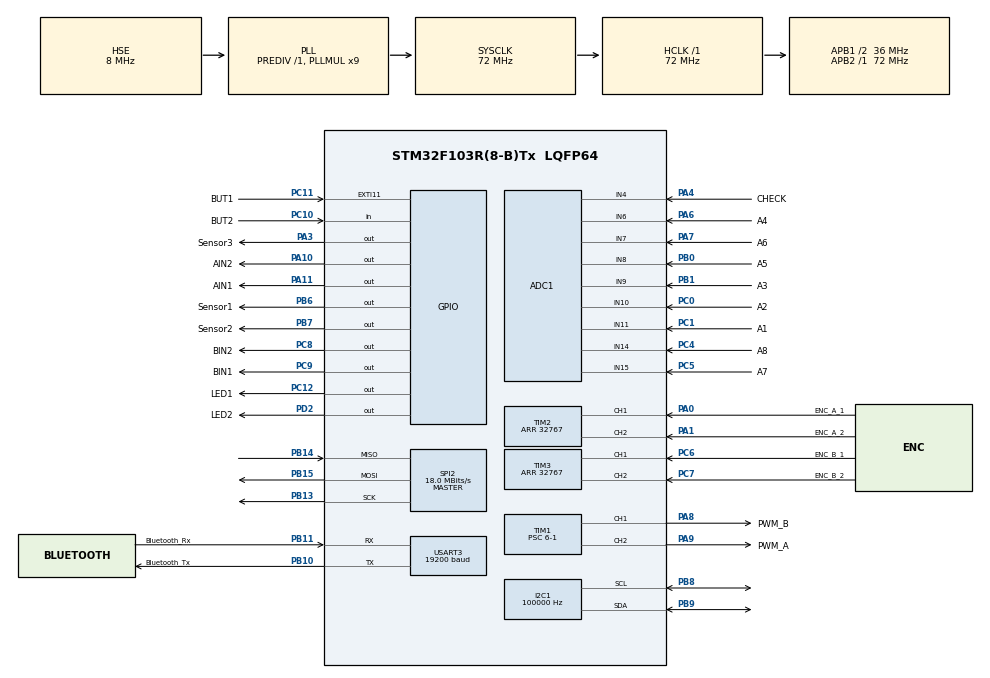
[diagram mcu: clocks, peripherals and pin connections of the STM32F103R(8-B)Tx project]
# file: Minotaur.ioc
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ADC1.Channel-361\#ChannelRegularConversion=ADC_CHANNEL_11
ADC1.Channel-367\#ChannelRegularConversion=ADC_CHANNEL_10
ADC1.Channel-368\#ChannelRegularConversion=ADC_CHANNEL_9
ADC1.Channel-369\#ChannelRegularConversion=ADC_CHANNEL_6
ADC1.Channel-370\#ChannelRegularConversion=ADC_CHANNEL_8
ADC1.Channel-371\#ChannelRegularConversion=ADC_CHANNEL_7
ADC1.ContinuousConvMode=ENABLE
ADC1.DataAlign=ADC_DATAALIGN_RIGHT
ADC1.DiscontinuousConvMode=DISABLE
ADC1.EnableAnalogWatchDog=false
ADC1.EnableRegularConversion=ENABLE
ADC1.ExternalTrigConvEdgeChoice=NONE
ADC1.InjNumberOfConversion=0
ADC1.NbrOfConversion=6
ADC1.NbrOfConversionFlag=1
ADC1.Rank-361\#ChannelRegularConversion=1
ADC1.Rank-367\#ChannelRegularConversion=2
ADC1.Rank-368\#ChannelRegularConversion=3
ADC1.Rank-369\#ChannelRegularConversion=4
ADC1.Rank-370\#ChannelRegularConversion=5
ADC1.Rank-371\#ChannelRegularConversion=6
ADC1.SamplingTime-361\#ChannelRegularConversion=ADC_SAMPLETIME_41CYCLES_5
ADC1.SamplingTime-367\#ChannelRegularConversion=ADC_SAMPLETIME_41CYCLES_5
ADC1.SamplingTime-368\#ChannelRegularConversion=ADC_SAMPLETIME_41CYCLES_5
ADC1.SamplingTime-369\#ChannelRegularConversion=ADC_SAMPLETIME_41CYCLES_5
ADC1.SamplingTime-370\#ChannelRegularConversion=ADC_SAMPLETIME_41CYCLES_5
ADC1.SamplingTime-371\#ChannelRegularConversion=ADC_SAMPLETIME_41CYCLES_5
ADC1.ScanConvMode=ADC_SCAN_ENABLE
ADC1.master=1
Dma.ADC1.0.Direction=DMA_PERIPH_TO_MEMORY
Dma.ADC1.0.Instance=DMA1_Channel1
Dma.ADC1.0.MemDataAlignment=DMA_MDATAALIGN_HALFWORD
Dma.ADC1.0.MemInc=DMA_MINC_ENABLE
Dma.ADC1.0.Mode=DMA_CIRCULAR
Dma.ADC1.0.PeriphDataAlignment=DMA_PDATAALIGN_HALFWORD
Dma.ADC1.0.PeriphInc=DMA_PINC_DISABLE
Dma.ADC1.0.Priority=DMA_PRIORITY_LOW
Dma.Request0=ADC1
Dma.Request1=USART3_TX
Dma.Request2=USART3_RX
Dma.USART3_RX.2.Direction=DMA_PERIPH_TO_MEMORY
Dma.USART3_RX.2.Instance=DMA1_Channel3
Dma.USART3_RX.2.MemDataAlignment=DMA_MDATAALIGN_BYTE
Dma.USART3_RX.2.MemInc=DMA_MINC_ENABLE
Dma.USART3_RX.2.Mode=DMA_CIRCULAR
Dma.USART3_RX.2.PeriphDataAlignment=DMA_PDATAALIGN_BYTE
Dma.USART3_RX.2.PeriphInc=DMA_PINC_DISABLE
Dma.USART3_RX.2.Priority=DMA_PRIORITY_LOW
Dma.USART3_TX.1.Direction=DMA_MEMORY_TO_PERIPH
Dma.USART3_TX.1.Instance=DMA1_Channel2
Dma.USART3_TX.1.MemDataAlignment=DMA_MDATAALIGN_BYTE
Dma.USART3_TX.1.MemInc=DMA_MINC_ENABLE
Dma.USART3_TX.1.Mode=DMA_NORMAL
Dma.USART3_TX.1.PeriphDataAlignment=DMA_PDATAALIGN_BYTE
Dma.USART3_TX.1.PeriphInc=DMA_PINC_DISABLE
Dma.USART3_TX.1.Priority=DMA_PRIORITY_LOW
I2C1.ClockSpeed=100000
I2C1.OwnAddress=0
Mcu.Family=STM32F1
Mcu.Name=STM32F103R(8-B)Tx
Mcu.Package=LQFP64
NVIC.DMA1_Channel1_IRQn=true\:1\:0\:true
NVIC.DMA1_Channel2_IRQn=true\:2\:0\:true
NVIC.DMA1_Channel3_IRQn=true\:2\:0\:true
NVIC.EXTI15_10_IRQn=true\:0\:0\:false
NVIC.PriorityGroup=NVIC_PRIORITYGROUP_4
NVIC.TIM4_IRQn=true\:0\:0\:false
NVIC.USART3_IRQn=true\:2\:0\:true
PA0-WKUP.GPIO_Label=ENC_A_1
PA0-WKUP.GPIO_PuPd=GPIO_NOPULL
PA0-WKUP.Signal=S_TIM2_CH1_ETR
PA1.GPIO_Label=ENC_A_2
PA1.GPIO_PuPd=GPIO_NOPULL
PA1.Signal=S_TIM2_CH2
PA10.GPIO_Label=AIN2
PA10.Signal=GPIO_Output
PA11.GPIO_Label=AIN1
PA11.Signal=GPIO_Output
PA13.Mode=Trace_Asynchronous_SW
PA13.Signal=SYS_JTMS-SWDIO
PA14.Mode=Trace_Asynchronous_SW
PA14.Signal=SYS_JTCK-SWCLK
PA3.GPIO_Label=Sensor3
PA3.Signal=GPIO_Output
PA4.GPIO_Label=CHECK
PA4.Signal=ADCx_IN4
PA6.GPIO_Label=A4
PA6.Signal=ADCx_IN6
PA7.GPIO_Label=A6
PA7.Signal=ADCx_IN7
PA8.GPIO_Label=PWM_B
PA8.Signal=S_TIM1_CH1
PA9.GPIO_Label=PWM_A
PA9.Signal=S_TIM1_CH2
PB0.GPIO_Label=A5
PB0.Signal=ADCx_IN8
PB1.GPIO_Label=A3
PB1.Signal=ADCx_IN9
PB10.GPIO_Label=Bluetooth_Tx
PB10.Mode=Asynchronous
PB10.Signal=USART3_TX
PB11.GPIO_Label=Bluetooth_Rx
PB11.Mode=Asynchronous
PB11.Signal=USART3_RX
PB13.Mode=Full_Duplex_Master
PB13.Signal=SPI2_SCK
PB14.Mode=Full_Duplex_Master
PB14.Signal=SPI2_MISO
PB15.Mode=Full_Duplex_Master
PB15.Signal=SPI2_MOSI
PB3.Mode=Trace_Asynchronous_SW
PB3.Signal=SYS_JTDO-TRACESWO
PB6.GPIO_Label=Sensor1
PB6.Signal=GPIO_Output
PB7.GPIO_Label=Sensor2
PB7.Signal=GPIO_Output
PB8.Mode=I2C
PB8.Signal=I2C1_SCL
PB9.Mode=I2C
PB9.Signal=I2C1_SDA
PC0.GPIO_Label=A2
PC0.Signal=ADCx_IN10
PC1.GPIO_Label=A1
PC1.Signal=ADCx_IN11
PC10.GPIO_Label=BUT2
PC10.Signal=GPIO_Input
PC11.GPIO_Label=BUT1
PC11.Signal=GPXTI11
PC12.GPIO_Label=LED1
PC12.Signal=GPIO_Output
PC14-OSC32_IN.Mode=LSE-External-Oscillator
PC14-OSC32_IN.Signal=RCC_OSC32_IN
PC15-OSC32_OUT.Mode=LSE-External-Oscillator
PC15-OSC32_OUT.Signal=RCC_OSC32_OUT
PC4.GPIO_Label=A8
PC4.Signal=ADCx_IN14
PC5.GPIO_Label=A7
PC5.Signal=ADCx_IN15
PC6.GPIO_Label=ENC_B_1
PC6.Signal=S_TIM3_CH1
PC7.GPIO_Label=ENC_B_2
PC7.Signal=S_TIM3_CH2
PC8.GPIO_Label=BIN2
PC8.Signal=GPIO_Output
PC9.GPIO_Label=BIN1
PC9.Signal=GPIO_Output
PD0-OSC_IN.Mode=HSE-External-Oscillator
PD0-OSC_IN.Signal=RCC_OSC_IN
PD1-OSC_OUT.Mode=HSE-External-Oscillator
PD1-OSC_OUT.Signal=RCC_OSC_OUT
PD2.GPIO_Label=LED2
PD2.Signal=GPIO_Output
ProjectManager.TargetToolchain=TrueSTUDIO
RCC.ADCPresc=RCC_ADCPCLK2_DIV6
RCC.AHBFreq_Value=72000000
RCC.APB1CLKDivider=RCC_HCLK_DIV2
RCC.APB1Freq_Value=36000000
RCC.APB1TimFreq_Value=72000000
RCC.APB2Freq_Value=72000000
RCC.APB2TimFreq_Value=72000000
RCC.HCLKFreq_Value=72000000
RCC.HSIState=RCC_HSI_ON
RCC.PLLMUL=RCC_PLL_MUL9
RCC.PLLSourceVirtual=RCC_PLLSOURCE_HSE
RCC.SYSCLKFreq_VALUE=72000000
RCC.SYSCLKSource=RCC_SYSCLKSOURCE_PLLCLK
RCC.USBFreq_Value=72000000
SH.ADCx_IN10.0=ADC1_IN10,IN10
SH.ADCx_IN11.0=ADC1_IN11,IN11
SH.ADCx_IN14.0=ADC1_IN14,IN14
SH.ADCx_IN15.0=ADC1_IN15,IN15
SH.ADCx_IN4.0=ADC1_IN4,IN4
SH.ADCx_IN6.0=ADC1_IN6,IN6
SH.ADCx_IN7.0=ADC1_IN7,IN7
SH.ADCx_IN8.0=ADC1_IN8,IN8
SH.ADCx_IN9.0=ADC1_IN9,IN9
SH.S_TIM1_CH1.0=TIM1_CH1,PWM Generation1 CH1
SH.S_TIM1_CH2.0=TIM1_CH2,PWM Generation2 CH2
SH.S_TIM2_CH1_ETR.0=TIM2_CH1,Encoder_Interface
SH.S_TIM2_CH2.0=TIM2_CH2,Encoder_Interface
SH.S_TIM3_CH1.0=TIM3_CH1,Encoder_Interface
SH.S_TIM3_CH2.0=TIM3_CH2,Encoder_Interface
SPI2.CalculateBaudRate=18.0 MBits/s
SPI2.Mode=SPI_MODE_MASTER
TIM1.Channel-PWM\ Generation2\ CH2=TIM_CHANNEL_2
TIM1.OCMode_PWM-PWM\ Generation2\ CH2=TIM_OCMODE_PWM1
TIM1.Period=999
TIM1.Prescaler=6-1
TIM2.CounterMode=TIM_COUNTERMODE_UP
TIM2.EncoderMode=TIM_ENCODERMODE_TI12
TIM2.IC1Polarity=TIM_ICPOLARITY_RISING
TIM2.IC2Polarity=TIM_ICPOLARITY_FALLING
TIM2.Period=32767
TIM3.CounterMode=TIM_COUNTERMODE_UP
TIM3.EncoderMode=TIM_ENCODERMODE_TI12
TIM3.IC2Polarity=TIM_ICPOLARITY_FALLING
TIM3.Period=32767
TIM4.Period=1000-1
TIM4.Prescaler=72-1
TIM4.TIM_MasterOutputTrigger=TIM_TRGO_ENABLE
USART3.BaudRate=19200
VP_RTC_No_RTC_Output.Mode=RTC OUT
VP_TIM1_VS_ClockSourceINT.Mode=Internal
VP_TIM4_VS_ClockSourceINT.Mode=Internal
board=Minotaur

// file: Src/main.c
/**
  ******************************************************************************
  * File Name          : main.c
  * Description        : Main program body
  ******************************************************************************
  *
  * COPYRIGHT(c) 2016 STMicroelectronics
  *
  * Redistribution and use in source and binary forms, with or without modification,
  * are permitted provided that the following conditions are met:
  *   1. Redistributions of source code must retain the above copyright notice,
  *      this list of conditions and the following disclaimer.
  *   2. Redistributions in binary form must reproduce the above copyright notice,
  *      this list of conditions and the following disclaimer in the documentation
  *      and/or other materials provided with the distribution.
  *   3. Neither the name of STMicroelectronics nor the names of its contributors
  *      may be used to endorse or promote products derived from this software
  *      without specific prior written permission.
  *
  * THIS SOFTWARE IS PROVIDED BY THE COPYRIGHT HOLDERS AND CONTRIBUTORS "AS IS"
  * AND ANY EXPRESS OR IMPLIED WARRANTIES, INCLUDING, BUT NOT LIMITED TO, THE
  * IMPLIED WARRANTIES OF MERCHANTABILITY AND FITNESS FOR A PARTICULAR PURPOSE ARE
  * DISCLAIMED. IN NO EVENT SHALL THE COPYRIGHT HOLDER OR CONTRIBUTORS BE LIABLE
  * FOR ANY DIRECT, INDIRECT, INCIDENTAL, SPECIAL, EXEMPLARY, OR CONSEQUENTIAL
  * DAMAGES (INCLUDING, BUT NOT LIMITED TO, PROCUREMENT OF SUBSTITUTE GOODS OR
  * SERVICES; LOSS OF USE, DATA, OR PROFITS; OR BUSINESS INTERRUPTION) HOWEVER
  * CAUSED AND ON ANY THEORY OF LIABILITY, WHETHER IN CONTRACT, STRICT LIABILITY,
  * OR TORT (INCLUDING NEGLIGENCE OR OTHERWISE) ARISING IN ANY WAY OUT OF THE USE
  * OF THIS SOFTWARE, EVEN IF ADVISED OF THE POSSIBILITY OF SUCH DAMAGE.
  *
  ******************************************************************************
  */
#include "stm32f1xx_hal.h"

/* USER CODE BEGIN Includes */
#include "main.h"
/* USER CODE END Includes */

ADC_HandleTypeDef hadc1;
DMA_HandleTypeDef hdma_adc1;

I2C_HandleTypeDef hi2c1;

RTC_HandleTypeDef hrtc;

SPI_HandleTypeDef hspi2;

TIM_HandleTypeDef htim1;
TIM_HandleTypeDef htim2;
TIM_HandleTypeDef htim3;
TIM_HandleTypeDef htim4;

UART_HandleTypeDef huart3;
DMA_HandleTypeDef hdma_usart3_tx;
DMA_HandleTypeDef hdma_usart3_rx;

/* USER CODE BEGIN PV */
/* Private variables ---------------------------------------------------------*/

/* USER CODE END PV */

void SystemClock_Config(void);
static void MX_GPIO_Init(void);
static void MX_DMA_Init(void);
static void MX_ADC1_Init(void);
static void MX_I2C1_Init(void);
static void MX_RTC_Init(void);
static void MX_SPI2_Init(void);
static void MX_TIM1_Init(void);
static void MX_TIM2_Init(void);
static void MX_TIM3_Init(void);
static void MX_TIM4_Init(void);
static void MX_USART3_UART_Init(void);

/* USER CODE BEGIN PFP */
/* Private function prototypes -----------------------------------------------*/

/* USER CODE END PFP */

int main(void)
{

  /* MCU Configuration----------------------------------------------------------*/

  /* Reset of all peripherals, Initializes the Flash interface and the Systick. */
  HAL_Init();

  /* Configure the system clock */
  SystemClock_Config();

  /* Initialize all configured peripherals */
  MX_GPIO_Init();
  MX_DMA_Init();
  MX_ADC1_Init();
  MX_I2C1_Init();
  MX_RTC_Init();
  MX_SPI2_Init();
  MX_TIM1_Init();
  MX_TIM2_Init();
  MX_TIM3_Init();
  MX_TIM4_Init();
  MX_USART3_UART_Init();

  /* USER CODE BEGIN 2 */
	encoderInit();
	pwmInit();
//	adcInit();
	uartInit();
	timInterruptInit();
	gyroInit(GYROHIGH);
	calibrateGyro();

//	rotaryRight(800);
//	HAL_Delay(500);
//	rotaryLeft(800);
	drive(VEL);

  /* USER CODE END 2 */

  /* Infinite loop */
  while (1)
  {

  }

}

/** System Clock Configuration
*/
void SystemClock_Config(void)
{

  RCC_OscInitTypeDef RCC_OscInitStruct;
  RCC_ClkInitTypeDef RCC_ClkInitStruct;
  RCC_PeriphCLKInitTypeDef PeriphClkInit;

  RCC_OscInitStruct.OscillatorType = RCC_OSCILLATORTYPE_LSI|RCC_OSCILLATORTYPE_HSE;
  RCC_OscInitStruct.HSEState = RCC_HSE_ON;
  RCC_OscInitStruct.HSEPredivValue = RCC_HSE_PREDIV_DIV1;
  RCC_OscInitStruct.LSIState = RCC_LSI_ON;
  RCC_OscInitStruct.PLL.PLLState = RCC_PLL_ON;
  RCC_OscInitStruct.PLL.PLLSource = RCC_PLLSOURCE_HSE;
  RCC_OscInitStruct.PLL.PLLMUL = RCC_PLL_MUL9;
  HAL_RCC_OscConfig(&RCC_OscInitStruct);

  RCC_ClkInitStruct.ClockType = RCC_CLOCKTYPE_SYSCLK|RCC_CLOCKTYPE_PCLK1;
  RCC_ClkInitStruct.SYSCLKSource = RCC_SYSCLKSOURCE_PLLCLK;
  RCC_ClkInitStruct.AHBCLKDivider = RCC_SYSCLK_DIV1;
  RCC_ClkInitStruct.APB1CLKDivider = RCC_HCLK_DIV2;
  RCC_ClkInitStruct.APB2CLKDivider = RCC_HCLK_DIV1;
  HAL_RCC_ClockConfig(&RCC_ClkInitStruct, FLASH_LATENCY_2);

  PeriphClkInit.PeriphClockSelection = RCC_PERIPHCLK_RTC|RCC_PERIPHCLK_ADC;
  PeriphClkInit.RTCClockSelection = RCC_RTCCLKSOURCE_LSI;
  PeriphClkInit.AdcClockSelection = RCC_ADCPCLK2_DIV6;
  HAL_RCCEx_PeriphCLKConfig(&PeriphClkInit);

  HAL_SYSTICK_Config(HAL_RCC_GetHCLKFreq()/1000);

  HAL_SYSTICK_CLKSourceConfig(SYSTICK_CLKSOURCE_HCLK);

  /* SysTick_IRQn interrupt configuration */
  HAL_NVIC_SetPriority(SysTick_IRQn, 0, 0);
}

/* ADC1 init function */
void MX_ADC1_Init(void)
{

  ADC_ChannelConfTypeDef sConfig;

    /**Common config
    */
  hadc1.Instance = ADC1;
  hadc1.Init.ScanConvMode = ADC_SCAN_ENABLE;
  hadc1.Init.ContinuousConvMode = ENABLE;
  hadc1.Init.DiscontinuousConvMode = DISABLE;
  hadc1.Init.ExternalTrigConv = ADC_SOFTWARE_START;
  hadc1.Init.DataAlign = ADC_DATAALIGN_RIGHT;
  hadc1.Init.NbrOfConversion = 6;
  HAL_ADC_Init(&hadc1);

    /**Configure Regular Channel
    */
  sConfig.Channel = ADC_CHANNEL_11;
  sConfig.Rank = 1;
  sConfig.SamplingTime = ADC_SAMPLETIME_7CYCLES_5;
  HAL_ADC_ConfigChannel(&hadc1, &sConfig);

    /**Configure Regular Channel
    */
  sConfig.Channel = ADC_CHANNEL_10;
  sConfig.Rank = 2;
  HAL_ADC_ConfigChannel(&hadc1, &sConfig);

    /**Configure Regular Channel
    */
  sConfig.Channel = ADC_CHANNEL_9;
  sConfig.Rank = 3;
  HAL_ADC_ConfigChannel(&hadc1, &sConfig);

    /**Configure Regular Channel
    */
  sConfig.Channel = ADC_CHANNEL_6;
  sConfig.Rank = 4;
  HAL_ADC_ConfigChannel(&hadc1, &sConfig);

    /**Configure Regular Channel
    */
  sConfig.Channel = ADC_CHANNEL_8;
  sConfig.Rank = 5;
  HAL_ADC_ConfigChannel(&hadc1, &sConfig);

    /**Configure Regular Channel
    */
  sConfig.Channel = ADC_CHANNEL_7;
  sConfig.Rank = 6;
  HAL_ADC_ConfigChannel(&hadc1, &sConfig);

}

/* I2C1 init function */
void MX_I2C1_Init(void)
{

  hi2c1.Instance = I2C1;
  hi2c1.Init.ClockSpeed = 100000;
  hi2c1.Init.DutyCycle = I2C_DUTYCYCLE_2;
  hi2c1.Init.OwnAddress1 = 0;
  hi2c1.Init.AddressingMode = I2C_ADDRESSINGMODE_7BIT;
  hi2c1.Init.DualAddressMode = I2C_DUALADDRESS_DISABLED;
  hi2c1.Init.OwnAddress2 = 0;
  hi2c1.Init.GeneralCallMode = I2C_GENERALCALL_DISABLED;
  hi2c1.Init.NoStretchMode = I2C_NOSTRETCH_DISABLED;
  HAL_I2C_Init(&hi2c1);

}

/* RTC init function */
void MX_RTC_Init(void)
{

  RTC_TimeTypeDef sTime;
  RTC_DateTypeDef DateToUpdate;

    /**Initialize RTC and set the Time and Date
    */
  hrtc.Instance = RTC;
  hrtc.Init.AsynchPrediv = RTC_AUTO_1_SECOND;
  hrtc.Init.OutPut = RTC_OUTPUTSOURCE_NONE;
  HAL_RTC_Init(&hrtc);

  sTime.Hours = 0x0;
  sTime.Minutes = 0x0;
  sTime.Seconds = 0x0;

  HAL_RTC_SetTime(&hrtc, &sTime, FORMAT_BCD);

  DateToUpdate.WeekDay = RTC_WEEKDAY_MONDAY;
  DateToUpdate.Month = RTC_MONTH_JANUARY;
  DateToUpdate.Date = 0x1;
  DateToUpdate.Year = 0x0;

  HAL_RTC_SetDate(&hrtc, &DateToUpdate, FORMAT_BCD);

}

/* SPI2 init function */
void MX_SPI2_Init(void)
{

  hspi2.Instance = SPI2;
  hspi2.Init.Mode = SPI_MODE_MASTER;
  hspi2.Init.Direction = SPI_DIRECTION_2LINES;
  hspi2.Init.DataSize = SPI_DATASIZE_8BIT;
  hspi2.Init.CLKPolarity = SPI_POLARITY_LOW;
  hspi2.Init.CLKPhase = SPI_PHASE_1EDGE;
  hspi2.Init.NSS = SPI_NSS_SOFT;
  hspi2.Init.BaudRatePrescaler = SPI_BAUDRATEPRESCALER_2;
  hspi2.Init.FirstBit = SPI_FIRSTBIT_MSB;
  hspi2.Init.TIMode = SPI_TIMODE_DISABLED;
  hspi2.Init.CRCCalculation = SPI_CRCCALCULATION_DISABLED;
  hspi2.Init.CRCPolynomial = 10;
  HAL_SPI_Init(&hspi2);

}

/* TIM1 init function */
void MX_TIM1_Init(void)
{

  TIM_ClockConfigTypeDef sClockSourceConfig;
  TIM_MasterConfigTypeDef sMasterConfig;
  TIM_BreakDeadTimeConfigTypeDef sBreakDeadTimeConfig;
  TIM_OC_InitTypeDef sConfigOC;

  htim1.Instance = TIM1;
  htim1.Init.Prescaler = 6-1;
  htim1.Init.CounterMode = TIM_COUNTERMODE_UP;
  htim1.Init.Period = 999;
  htim1.Init.ClockDivision = TIM_CLOCKDIVISION_DIV1;
  htim1.Init.RepetitionCounter = 0;
  HAL_TIM_Base_Init(&htim1);

  sClockSourceConfig.ClockSource = TIM_CLOCKSOURCE_INTERNAL;
  HAL_TIM_ConfigClockSource(&htim1, &sClockSourceConfig);

  HAL_TIM_PWM_Init(&htim1);

  sMasterConfig.MasterOutputTrigger = TIM_TRGO_RESET;
  sMasterConfig.MasterSlaveMode = TIM_MASTERSLAVEMODE_DISABLE;
  HAL_TIMEx_MasterConfigSynchronization(&htim1, &sMasterConfig);

  sBreakDeadTimeConfig.OffStateRunMode = TIM_OSSR_DISABLE;
  sBreakDeadTimeConfig.OffStateIDLEMode = TIM_OSSI_DISABLE;
  sBreakDeadTimeConfig.LockLevel = TIM_LOCKLEVEL_OFF;
  sBreakDeadTimeConfig.DeadTime = 0;
  sBreakDeadTimeConfig.BreakState = TIM_BREAK_DISABLE;
  sBreakDeadTimeConfig.BreakPolarity = TIM_BREAKPOLARITY_HIGH;
  sBreakDeadTimeConfig.AutomaticOutput = TIM_AUTOMATICOUTPUT_DISABLE;
  HAL_TIMEx_ConfigBreakDeadTime(&htim1, &sBreakDeadTimeConfig);

  sConfigOC.OCMode = TIM_OCMODE_PWM1;
  sConfigOC.Pulse = 0;
  sConfigOC.OCPolarity = TIM_OCPOLARITY_HIGH;
  sConfigOC.OCNPolarity = TIM_OCNPOLARITY_HIGH;
  sConfigOC.OCFastMode = TIM_OCFAST_DISABLE;
  sConfigOC.OCIdleState = TIM_OCIDLESTATE_RESET;
  sConfigOC.OCNIdleState = TIM_OCNIDLESTATE_RESET;
  HAL_TIM_PWM_ConfigChannel(&htim1, &sConfigOC, TIM_CHANNEL_1);

  HAL_TIM_PWM_ConfigChannel(&htim1, &sConfigOC, TIM_CHANNEL_2);

}

/* TIM2 init function */
void MX_TIM2_Init(void)
{

  TIM_Encoder_InitTypeDef sConfig;
  TIM_MasterConfigTypeDef sMasterConfig;

  htim2.Instance = TIM2;
  htim2.Init.Prescaler = 0;
  htim2.Init.CounterMode = TIM_COUNTERMODE_UP;
  htim2.Init.Period = 32767;
  htim2.Init.ClockDivision = TIM_CLOCKDIVISION_DIV1;
  sConfig.EncoderMode = TIM_ENCODERMODE_TI12;
  sConfig.IC1Polarity = TIM_ICPOLARITY_RISING;
  sConfig.IC1Selection = TIM_ICSELECTION_DIRECTTI;
  sConfig.IC1Prescaler = TIM_ICPSC_DIV1;
  sConfig.IC1Filter = 0;
  sConfig.IC2Polarity = TIM_ICPOLARITY_FALLING;
  sConfig.IC2Selection = TIM_ICSELECTION_DIRECTTI;
  sConfig.IC2Prescaler = TIM_ICPSC_DIV1;
  sConfig.IC2Filter = 0;
  HAL_TIM_Encoder_Init(&htim2, &sConfig);

  sMasterConfig.MasterOutputTrigger = TIM_TRGO_RESET;
  sMasterConfig.MasterSlaveMode = TIM_MASTERSLAVEMODE_DISABLE;
  HAL_TIMEx_MasterConfigSynchronization(&htim2, &sMasterConfig);

}

/* TIM3 init function */
void MX_TIM3_Init(void)
{

  TIM_Encoder_InitTypeDef sConfig;
  TIM_MasterConfigTypeDef sMasterConfig;

  htim3.Instance = TIM3;
  htim3.Init.Prescaler = 0;
  htim3.Init.CounterMode = TIM_COUNTERMODE_UP;
  htim3.Init.Period = 32767;
  htim3.Init.ClockDivision = TIM_CLOCKDIVISION_DIV1;
  sConfig.EncoderMode = TIM_ENCODERMODE_TI12;
  sConfig.IC1Polarity = TIM_ICPOLARITY_RISING;
  sConfig.IC1Selection = TIM_ICSELECTION_DIRECTTI;
  sConfig.IC1Prescaler = TIM_ICPSC_DIV1;
  sConfig.IC1Filter = 0;
  sConfig.IC2Polarity = TIM_ICPOLARITY_FALLING;
  sConfig.IC2Selection = TIM_ICSELECTION_DIRECTTI;
  sConfig.IC2Prescaler = TIM_ICPSC_DIV1;
  sConfig.IC2Filter = 0;
  HAL_TIM_Encoder_Init(&htim3, &sConfig);

  sMasterConfig.MasterOutputTrigger = TIM_TRGO_RESET;
  sMasterConfig.MasterSlaveMode = TIM_MASTERSLAVEMODE_DISABLE;
  HAL_TIMEx_MasterConfigSynchronization(&htim3, &sMasterConfig);

}

/* TIM4 init function */
void MX_TIM4_Init(void)
{

  TIM_ClockConfigTypeDef sClockSourceConfig;
  TIM_MasterConfigTypeDef sMasterConfig;

  htim4.Instance = TIM4;
  htim4.Init.Prescaler = 72-1;
  htim4.Init.CounterMode = TIM_COUNTERMODE_UP;
  htim4.Init.Period = 250-1;
  htim4.Init.ClockDivision = TIM_CLOCKDIVISION_DIV1;
  HAL_TIM_Base_Init(&htim4);

  sClockSourceConfig.ClockSource = TIM_CLOCKSOURCE_INTERNAL;
  HAL_TIM_ConfigClockSource(&htim4, &sClockSourceConfig);

  sMasterConfig.MasterOutputTrigger = TIM_TRGO_ENABLE;
  sMasterConfig.MasterSlaveMode = TIM_MASTERSLAVEMODE_DISABLE;
  HAL_TIMEx_MasterConfigSynchronization(&htim4, &sMasterConfig);

}

/* USART3 init function */
void MX_USART3_UART_Init(void)
{

  huart3.Instance = USART3;
  huart3.Init.BaudRate = 19200;
  huart3.Init.WordLength = UART_WORDLENGTH_8B;
  huart3.Init.StopBits = UART_STOPBITS_1;
  huart3.Init.Parity = UART_PARITY_NONE;
  huart3.Init.Mode = UART_MODE_TX_RX;
  huart3.Init.HwFlowCtl = UART_HWCONTROL_NONE;
  huart3.Init.OverSampling = UART_OVERSAMPLING_16;
  HAL_UART_Init(&huart3);

}

void MX_DMA_Init(void)
{
  /* DMA controller clock enable */
  __HAL_RCC_DMA1_CLK_ENABLE();

  /* DMA interrupt init */
  HAL_NVIC_SetPriority(DMA1_Channel1_IRQn, 1, 0);
  HAL_NVIC_EnableIRQ(DMA1_Channel1_IRQn);
  HAL_NVIC_SetPriority(DMA1_Channel2_IRQn, 2, 0);
  HAL_NVIC_EnableIRQ(DMA1_Channel2_IRQn);
  HAL_NVIC_SetPriority(DMA1_Channel3_IRQn, 2, 0);
  HAL_NVIC_EnableIRQ(DMA1_Channel3_IRQn);

}

/** Configure pins as
        * Analog
        * Input
        * Output
        * EVENT_OUT
        * EXTI
*/
void MX_GPIO_Init(void)
{

  GPIO_InitTypeDef GPIO_InitStruct;

  /* GPIO Ports Clock Enable */
  __GPIOC_CLK_ENABLE();
  __GPIOD_CLK_ENABLE();
  __GPIOA_CLK_ENABLE();
  __GPIOB_CLK_ENABLE();

  /*Configure GPIO pins : Sensor3_Pin AIN2_Pin AIN1_Pin */
  GPIO_InitStruct.Pin = Sensor3_Pin|AIN2_Pin|AIN1_Pin;
  GPIO_InitStruct.Mode = GPIO_MODE_OUTPUT_PP;
  GPIO_InitStruct.Speed = GPIO_SPEED_LOW;
  HAL_GPIO_Init(GPIOA, &GPIO_InitStruct);

  /*Configure GPIO pins : BIN2_Pin BIN1_Pin LED1_Pin */
  GPIO_InitStruct.Pin = BIN2_Pin|BIN1_Pin|LED1_Pin;
  GPIO_InitStruct.Mode = GPIO_MODE_OUTPUT_PP;
  GPIO_InitStruct.Speed = GPIO_SPEED_LOW;
  HAL_GPIO_Init(GPIOC, &GPIO_InitStruct);

  /*Configure GPIO pin : BUT2_Pin */
  GPIO_InitStruct.Pin = BUT2_Pin;
  GPIO_InitStruct.Mode = GPIO_MODE_INPUT;
  GPIO_InitStruct.Pull = GPIO_NOPULL;
  HAL_GPIO_Init(BUT2_GPIO_Port, &GPIO_InitStruct);

  /*Configure GPIO pin : BUT1_Pin */
  GPIO_InitStruct.Pin = BUT1_Pin;
  GPIO_InitStruct.Mode = GPIO_MODE_IT_RISING;
  GPIO_InitStruct.Pull = GPIO_NOPULL;
  HAL_GPIO_Init(BUT1_GPIO_Port, &GPIO_InitStruct);

  /*Configure GPIO pin : LED2_Pin */
  GPIO_InitStruct.Pin = LED2_Pin;
  GPIO_InitStruct.Mode = GPIO_MODE_OUTPUT_PP;
  GPIO_InitStruct.Speed = GPIO_SPEED_LOW;
  HAL_GPIO_Init(LED2_GPIO_Port, &GPIO_InitStruct);

  /*Configure GPIO pins : Sensor1_Pin Sensor2_Pin */
  GPIO_InitStruct.Pin = Sensor1_Pin|Sensor2_Pin;
  GPIO_InitStruct.Mode = GPIO_MODE_OUTPUT_PP;
  GPIO_InitStruct.Speed = GPIO_SPEED_LOW;
  HAL_GPIO_Init(GPIOB, &GPIO_InitStruct);

  /* EXTI interrupt init*/
  HAL_NVIC_SetPriority(EXTI15_10_IRQn, 0, 0);
  HAL_NVIC_EnableIRQ(EXTI15_10_IRQn);

}

/************************ (C) COPYRIGHT STMicroelectronics *****END OF FILE****/
